# GPIO register map
Vendor: Texas Instruments
Peripheral module from a debugger description file (folder UCD3138R064RSM).
Registers are 32-bit, write-only, no defined reset value unless marked. A register's access mark holds for its fields unless they carry their own. Offsets are as the file gives them; lines under a group give offsets from that group; [hi:lo] are bit positions; {n}, {i} and the like mark numbered series; 'fields as' and 'values as' point back to an identical list; <NAME> marks a mode.

## GPIO — **MCU** **GPIO** - I/F for controlling and reading **IO** status and **IO** event status INTERNAL_NOTE: [Functional Spec](https://spsemea.itg.ti.com/sites/lpw/proj/CC26xx/Modules/MCU_GPIO/MCU_GPIO_Func_Spec.docx) [IOC Overview Figure](https://spsemea.itg.ti.com/sites/lpw/proj/CC26xx/Modules/MCU_IOC/ioc_overview.vsd)
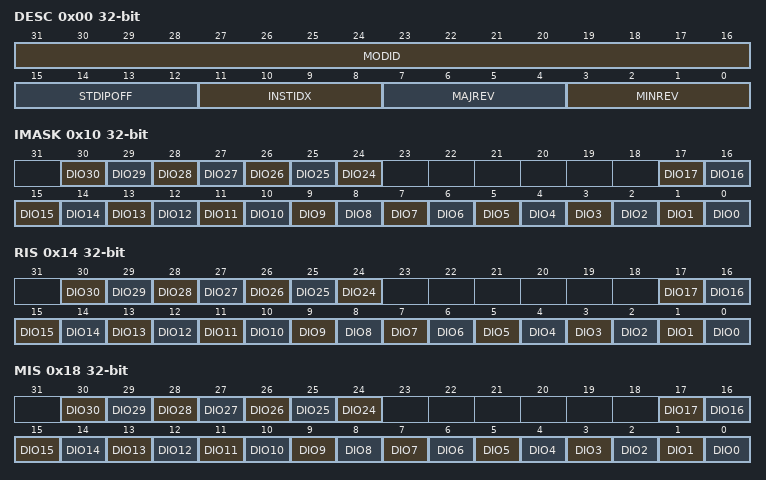
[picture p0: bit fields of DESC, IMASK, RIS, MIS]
0x00 DESC ro — Provides module ID, revision information, instance index
  [31:16] MODID — Module identifier
    0xFFFF=MAXIMUM (Highest possible value); 0=MINIMUM (Smallest value)
  [15:12] STDIPOFF — 0: STDIP MMRs do not exist 1:15: These MMRs begin at offset 64*STDIPOFF from IP base address
    15=MAXIMUM (Highest possible value); 0=MINIMUM (Smallest value)
  [11:8] INSTIDX — If multiple instances of IP exists in SOC, this field can identify the instance number 0-15
    values as STDIPOFF
  [7:4] MAJREV — Major revision version of IP
    values as STDIPOFF
  [3:0] MINREV — Minor revision version of IP
    values as STDIPOFF
0x04 DESCEX ro — Provide IP-specific instance information
  [5:0] NUMDIO — This provides the total number of DIOs supported by GPIO. The number of DIOs supprted is NUMDIO + 1
    63=MAXIMUM (Highest possible value); 0=MINIMUM (Smallest value)
0x10 IMASK rw — Interrupt mask for DIO pins
  [all] fields
    0=CLR (Clear Interrupt Mask); 1=SET (Set Interrrupt Mask)
  [n] DIO{n} (n=24..30) — Interrupt mask for DIO{n}
  [n] DIO{n} (n=0..17) — Interrupt mask for DIO{n}
0x14 RIS ro — Raw interrupt flag for DIO pins
  [all] fields
    0=CLR (Interrupt did not occur); 1=SET (Interrupt occured)
  [n] DIO{n} (n=24..30) — Raw interrupt flag for DIO{n}
  [n] DIO{n} (n=0..17) — Raw interrupt flag for DIO{n}
0x18 MIS ro — Masked interrupt flag for DIO pins
  [all] fields
    0=CLR (Interrupt did not occur); 1=SET (Interrupt occured)
  [n] DIO{n} (n=24..30) — Masked interrupt flag for DIO{n}
  [n] DIO{n} (n=0..17) — Masked interrupt flag for DIO{n}
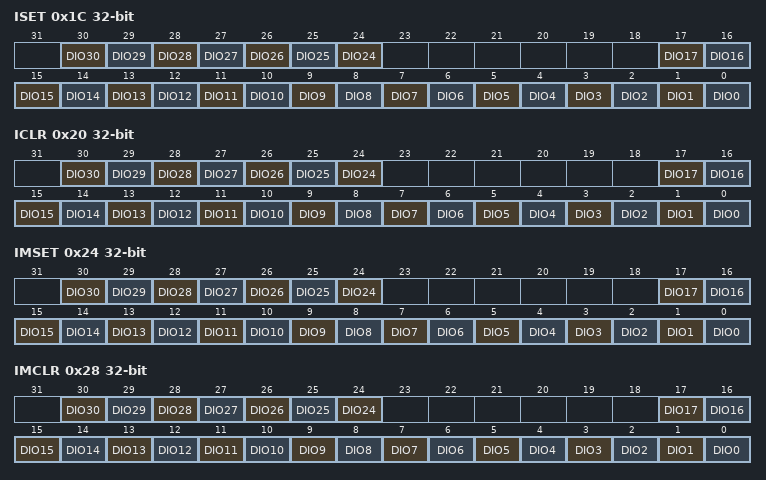
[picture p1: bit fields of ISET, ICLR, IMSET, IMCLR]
0x1C ISET — Set interrupt flag in RIS by writing a one
  [all] fields
    0=NO_EFFECT (Writing 0 has no effect); 1=SET (Set Interrupt)
  [n] DIO{n} (n=24..30) — Set DIO{n} in RIS
  [n] DIO{n} (n=0..17) — Set DIO{n} in RIS
0x20 ICLR — Clear interrupt flag in RIS by writing a one
  [all] fields
    0=NO_EFFECT (Writing 0 has no effect); 1=CLR (Clear Interrupt)
  [n] DIO{n} (n=24..30) — Clears DIO{n} in RIS
  [n] DIO{n} (n=0..17) — Clears DIO{n} in RIS
0x24 IMSET — Set interrupt mask in IMASK by writing a one
  [all] fields
    0=NO_EFFECT (Writing 0 has no effect); 1=SET (Set interrupt mask)
  [n] DIO{n} (n=24..30) — Sets DIO{n} in IMASK
  [n] DIO{n} (n=0..17) — Sets DIO{n} in IMASK
0x28 IMCLR — Clear interrupt mask in IMASK by writing a one
  [all] fields
    0=NO_EFFECT (Writing 0 has no effect); 1=CLR (Clear interrupt mask)
  [n] DIO{n} (n=24..30) — Clears DIO{n} in IMASK
  [n] DIO{n} (n=0..17) — Clears DIO{n} in IMASK
0x30 DTB rw — Digital test bus mux selection
  [2:0] SEL — DTB MUX select pin value
    0=DISABLE (DTB output from peripheral is 0x0.); {v}=GRP{v} (Selects test group {v}) (v=1..7)
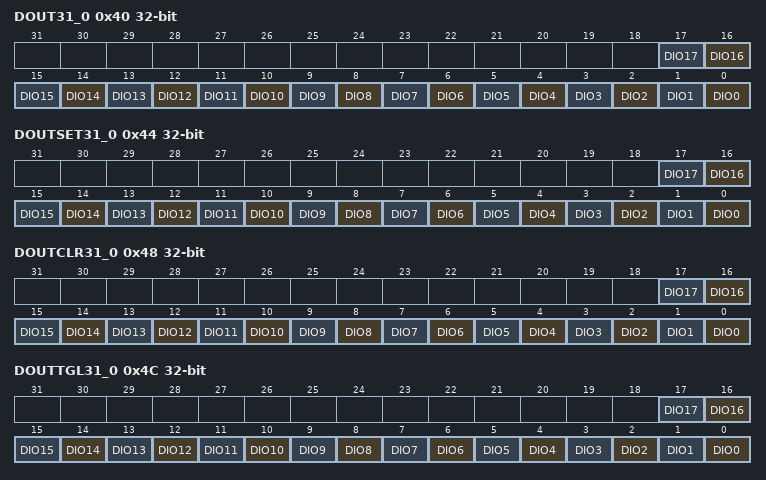
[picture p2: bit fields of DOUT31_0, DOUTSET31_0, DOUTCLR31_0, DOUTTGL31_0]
0x40 DOUT31_0 rw — Data Output for DIO 31 to 0 pins.
  [all] fields
    0=ZERO (Output is set to 0); 1=ONE (Output is set to 1)
  [n] DIO{n} (n=0..17) — Data output for DIO{n}
0x44 DOUTSET31_0 — Data output set for DIO 31 to 0 pins. Writing 1 to a bit position sets the corresponding bit in the DOUT31_0 register.
  [all] fields
    0=NO_EFFECT; 1=SET
  [n] DIO{n} (n=0..17) — Set bit DIO{n} in DOUT31_0
0x48 DOUTCLR31_0 — Data output clear for DIO 31 to 0 pins. Writing 1 to a bit position clears the corresponding bit in the DOUT31_0 register.
  [all] fields
    0=NO_EFFECT; 1=CLR (Clear)
  [n] DIO{n} (n=0..17) — Clear bit DIO{n} in DOUT31_0
0x4C DOUTTGL31_0 — Data output toggle for DIO 31 to 0 pins. Writing 1 to a bit position will invert the corresponding bit in DOUT31_0 register.
  [all] fields
    0=NO_EFFECT; 1=TOGGLE
  [n] DIO{n} (n=0..17) — Toggles bit DIO{n} in DOUT31_0
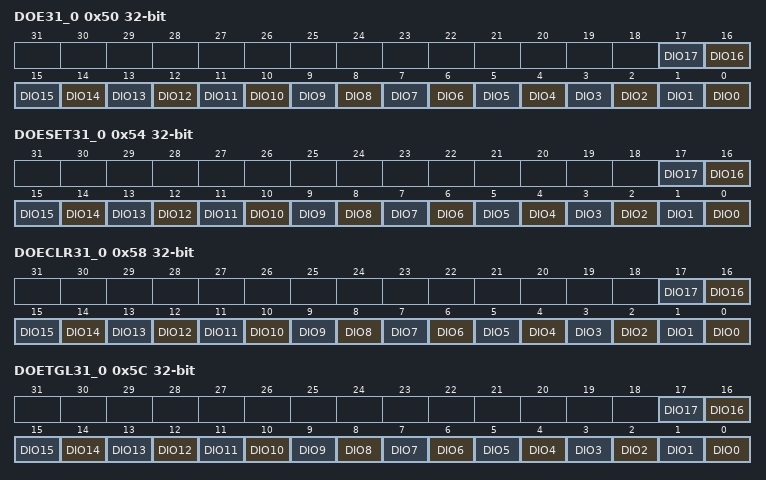
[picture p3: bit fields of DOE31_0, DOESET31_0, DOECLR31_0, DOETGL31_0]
0x50 DOE31_0 rw — Data output enable for DIO 31 to 0 pins.
  [all] fields
    0=DISABLE (Output disabled); 1=ENABLE (Output enabled)
  [n] DIO{n} (n=0..17) — Data output enable for DIO{n}
0x54 DOESET31_0 — Data output enable set for DIO 31 to 0 pins. Writing 1 to a bit position sets the corresponding bit in the DOE31_0 register.
  [all] fields
    0=NO_EFFECT; 1=SET
  [n] DIO{n} (n=0..17) — Set bit DIO{n} in DOE31_0
0x58 DOECLR31_0 — Data output enable clear for DIO 31 to 0 pins. Writing 1 to a bit position clears the corresponding bit in the DOE31_0 register.
  [all] fields
    0=NO_EFFECT; 1=CLR (Clear)
  [n] DIO{n} (n=0..17) — Clears bit DIO{n} in DOE31_0
0x5C DOETGL31_0 — Data output enable toggle for DIO 31 to 0 pins. Writing 1 to a bit position will invert the corresponding bit in DOE31_0 register.
  [all] fields
    0=NO_EFFECT; 1=TOGGLE
  [n] DIO{n} (n=0..17) — Toggles bit DIO{n} in DOE31_0
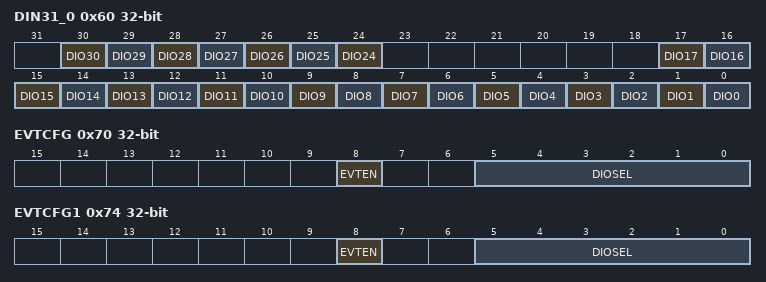
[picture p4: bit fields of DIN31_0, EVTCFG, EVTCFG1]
0x60 DIN31_0 ro — Data input from DIO 31 to 0 pins.
  [all] fields
    0=ZERO (Input value is 0); 1=ONE (Input value is 1)
  [n] DIO{n} (n=24..30) — Data input from DIO{n}
  [n] DIO{n} (n=0..17) — Data input from DIO{n}
0x70 EVTCFG rw — Event configuration 0. This register is used to select DIO for GPIO to publish event on SVT event fabric. It also contains enable bit that is used to mask the event.
  [8] EVTEN — Enables GPIO to publish edge qualified selected DIO event on SVT event fabric. Design note: The edge detector flop is cleared automatically for the selected DIO once the event is published.
    0=DISABLE; 1=ENABLE
  [5:0] DIOSEL — This is used to select DIO for event generation. For example, DIOSEL = 0x0 selects DIO0 and DIOSEL = 0x8 selects DIO8.
    0=MINIMUM (Minimum value); 63=MAXIMUM (Maximum value)
0x74 EVTCFG1 rw — Event configuration 1. This register is used to select DIO for GPIO to publish event on SVT event fabric. It also contains enable bit that is used to mask the event.
  fields as EVTCFG
